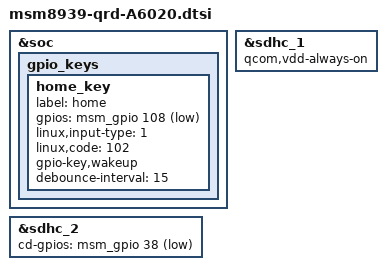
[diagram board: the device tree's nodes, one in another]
/* Copyright (c) 2014, The Linux Foundation. All rights reserved.
 *
 * This program is free software; you can redistribute it and/or modify
 * it under the terms of the GNU General Public License version 2 and
 * only version 2 as published by the Free Software Foundation.
 *
 * This program is distributed in the hope that it will be useful,
 * but WITHOUT ANY WARRANTY; without even the implied warranty of
 * MERCHANTABILITY or FITNESS FOR A PARTICULAR PURPOSE.  See the
 * GNU General Public License for more details.
 */

&soc {
	gpio_keys {
		home_key {
			label = "home";
			gpios = <&msm_gpio 108 0x1>;
			linux,input-type = <1>;
			linux,code = <102>;
			gpio-key,wakeup;
			debounce-interval = <15>;
		};
	};
};

&sdhc_1 {
	qcom,vdd-always-on;
};

&sdhc_2 {
	cd-gpios = <&msm_gpio 38 0x1>;
};


